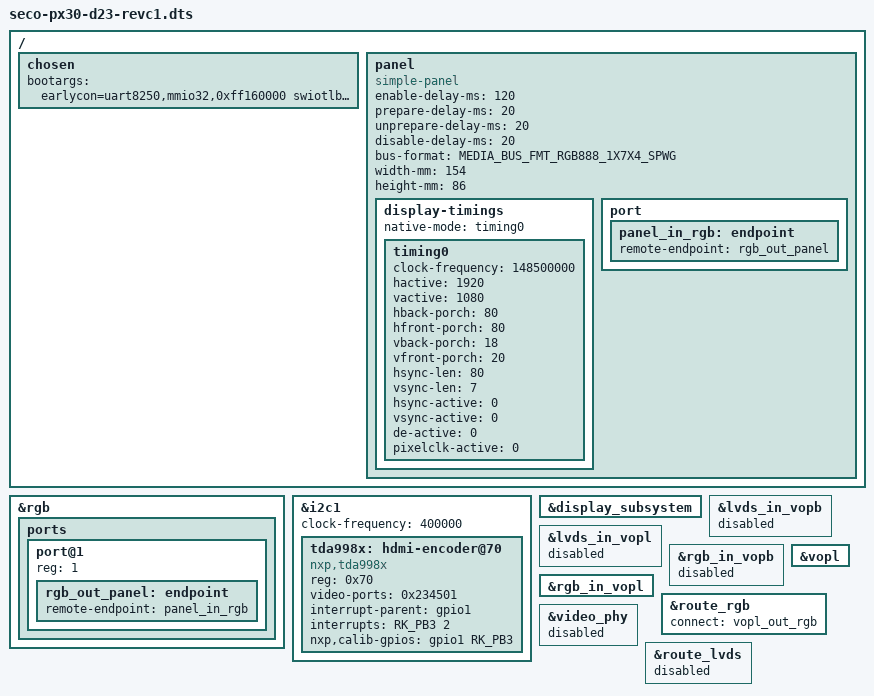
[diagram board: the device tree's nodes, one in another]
// SPDX-License-Identifier: (GPL-2.0+ OR MIT)
/*
 * Copyright (c) 2018 Fuzhou Rockchip Electronics Co., Ltd
 */

/dts-v1/;

#include <dt-bindings/display/tda998x.h>
#include "seco-px30-d23-revc1.dtsi"

/ {
	chosen {
		bootargs = "earlycon=uart8250,mmio32,0xff160000 swiotlb=1 console=ttyFIQ0 rw rootwait board_revC1-HDMI";
	};

	panel {
		compatible = "simple-panel";
		enable-delay-ms = <120>;
		prepare-delay-ms = <20>;
		unprepare-delay-ms = <20>;
		disable-delay-ms = <20>;
		bus-format = <MEDIA_BUS_FMT_RGB888_1X7X4_SPWG>;

		width-mm = <154>;
		height-mm = <86>;

		display-timings {
			native-mode = <&timing0>;

			timing0: timing0 {
				clock-frequency = <148500000>;
				hactive = <1920>;
				vactive = <1080>;
				hback-porch = <80>;
				hfront-porch = <80>;
				vback-porch = <18>;
				vfront-porch = <20>;
				hsync-len = <80>;
				vsync-len = <7>;
				hsync-active = <0>;
				vsync-active = <0>;
				de-active = <0>;
				pixelclk-active = <0>;
			};
		};

		port {
			panel_in_rgb: endpoint {
				remote-endpoint = <&rgb_out_panel>;
			};
		};
	};
};

&rgb {
	status = "okay";
 
    ports {
        port@1 {
            reg = <1>;

            rgb_out_panel: endpoint {
                remote-endpoint = <&panel_in_rgb>;
            };
        };
    };
};

&i2c1 {
	status = "okay";
	clock-frequency = <400000>;

	tda998x: hdmi-encoder@70 {
		compatible = "nxp,tda998x";
		reg = <0x70>;
        	video-ports = <0x234501>;
		interrupt-parent = <&gpio1>;
		interrupts = <RK_PB3 2>;		/* falling edge */
        	nxp,calib-gpios = <&gpio1 RK_PB3 2>;
	};
};

// &dmc {
// 	auto-freq-en = <0>;
// };

&display_subsystem {
	status = "okay";
};

&lvds_in_vopb {
	status = "disabled";
};

&lvds_in_vopl {
	status = "disabled";
};

&rgb_in_vopb {
	status = "disabled";
};

&rgb_in_vopl {
	status = "okay";
};

&vopl {
	status = "okay";
};

&route_rgb {
	connect = <&vopl_out_rgb>;
	status = "okay";
};

&video_phy {
	status = "disabled";
};

&route_lvds {
	status = "disabled";
};
